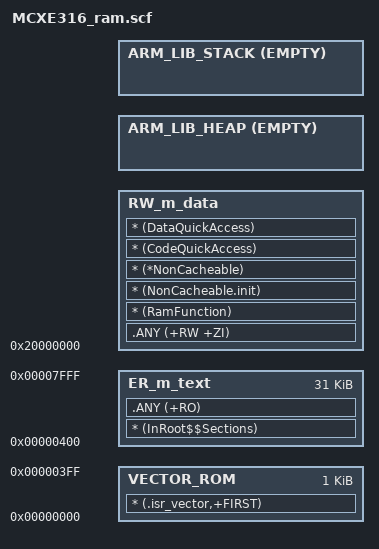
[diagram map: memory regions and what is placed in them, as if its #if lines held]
#!armclang --target=arm-arm-none-eabi -mcpu=cortex-m7 -E -x c

/*
** ###################################################################
**     Processors:          MCXE316MLF_M7
**                          MCXE316MPA_M7
**
**     Compiler:            Keil ARM C/C++ Compiler
**     Reference manual:    MCXE31 RM Rev2
**     Version:             rev. 1.0, 2024-12-27
**     Build:               b250825
**
**     Abstract:
**         Linker file for the Keil ARM C/C++ Compiler
**
**     Copyright 2016 Freescale Semiconductor, Inc.
**     Copyright 2016-2025 NXP
**     SPDX-License-Identifier: BSD-3-Clause
**
**     http:                 www.nxp.com
**     mail:                 support@nxp.com
**
** ###################################################################
*/

#define m_itcm_start                   0x00000000
#define m_itcm_end                     0x00007FFF

#define m_dtcm_start                   0x20000000
#define m_dtcm_end                     0x2000FFFF


#define m_interrupts_start             m_itcm_start
#define m_interrupts_size              0x00000400

#define m_text_start                   m_interrupts_start + m_interrupts_size
#define m_text_size                    m_itcm_end - m_itcm_start - m_interrupts_size + 1

#define m_data_start                   m_dtcm_start
#define m_data_size                    m_dtcm_end - m_dtcm_start + 1

/* Sizes */
#if (defined(__stack_size__))
  #define Stack_Size                   __stack_size__
#else
  #define Stack_Size                   0x0400
#endif

#if (defined(__heap_size__))
  #define Heap_Size                    __heap_size__
#else
  #define Heap_Size                    0x0400
#endif

LR_m_text m_text_start m_text_size {   ; load region size_region
  ER_m_text m_text_start m_text_size { ; load address = execution address
    * (InRoot$$Sections)
    .ANY (+RO)
  }

  RW_m_data m_data_start m_data_size-Stack_Size-Heap_Size { ; RW data
    .ANY (+RW +ZI)
    * (RamFunction)
    * (NonCacheable.init)
    * (*NonCacheable)
    * (CodeQuickAccess)
    * (DataQuickAccess)
  }

  ARM_LIB_HEAP +0 EMPTY Heap_Size {    ; Heap region growing up
  }
  ARM_LIB_STACK m_data_start+m_data_size EMPTY -Stack_Size { ; Stack region growing down
  }
}

LR_m_interrupts m_interrupts_start m_interrupts_size {
  VECTOR_ROM m_interrupts_start m_interrupts_size { ; load address = execution address
    * (.isr_vector,+FIRST)
  }
}

